# RSL15 register map
Vendor: ONSemiconductor; Series: RSL15 Series; File version: 1.0
CPU: CM33 r0p4, little endian, MPU, FPU, 3 interrupt priority bits
Registers are 32-bit, read-write, reset 0x0 unless marked. A register's access mark holds for its fields unless they carry their own. Offsets are from the block's base; [hi:lo] are bit positions; {n}, {i} and the like mark numbered series.

## RF0 (part 3 of 3) — RF Front-End 2.4 GHz
Base 0x40040800
Same registers: RF1 0x40040A00, RF2 0x40040C00
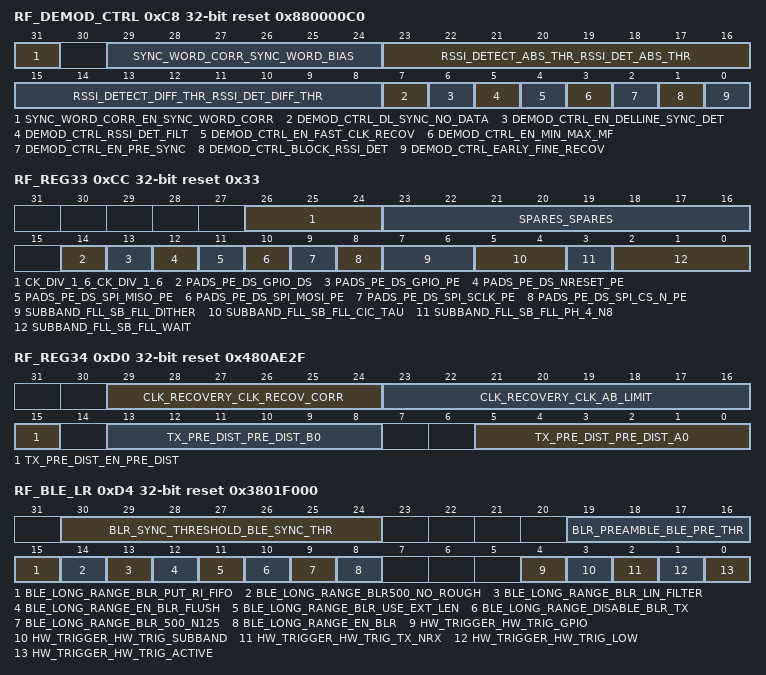
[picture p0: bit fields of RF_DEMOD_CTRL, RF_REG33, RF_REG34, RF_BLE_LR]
0xC8 RF_DEMOD_CTRL reset 0x880000C0 — DEMOD_CTRL
  [31] SYNC_WORD_CORR_EN_SYNC_WORD_CORR — Sync word bias correction with RSSI detection (banked)
    0=SYNC_WORD_CORR_EN_SYNC_WORD_CORR_DISABLE (Disable the sync word bias correction with RSSI detection); 1=SYNC_WORD_CORR_EN_SYNC_WORD_CORR_ENABLE (Enable the sync word bias correction with RSSI detection)
  [29:24] SYNC_WORD_CORR_SYNC_WORD_BIAS — Set the sync word bias (banked)
    8=SYNC_WORD_CORR_SYNC_WORD_BIAS_DEFAULT (Without the phase ADC rescaler, it's 8*mod_idx)
  [23:16] RSSI_DETECT_ABS_THR_RSSI_DET_ABS_THR — Threshold used for absolute RSSI detection
    0=RSSI_DETECT_ABS_THR_RSSI_DET_ABS_THR_DEFAULT
  [15:8] RSSI_DETECT_DIFF_THR_RSSI_DET_DIFF_THR — Threshold used for differential RSSI detection
    0=RSSI_DETECT_DIFF_THR_RSSI_DET_DIFF_THR_DEFAULT
  [7] DEMOD_CTRL_DL_SYNC_NO_DATA — No data going through the demodulator, until the delay line detects the sync word (banked)
    0=DEMOD_CTRL_DL_SYNC_NO_DATA_DISABLE; 1=DEMOD_CTRL_DL_SYNC_NO_DATA_ENABLE
  [6] DEMOD_CTRL_EN_DELLINE_SYNC_DET — Sync word detection in the delay line (banked)
    0=DEMOD_CTRL_EN_DELLINE_SYNC_DET_DISABLE (Disable the sync word detection in the delay line); 1=DEMOD_CTRL_EN_DELLINE_SYNC_DET_ENABLE (Enable the sync word detection in the delay line)
  [5] DEMOD_CTRL_RSSI_DET_FILT — Additional filtering on the RSSI value (banked)
    0=DEMOD_CTRL_RSSI_DET_FILT_DISABLE (Dont' add an additional filtering on the RSSI value); 1=DEMOD_CTRL_RSSI_DET_FILT_ENABLE (Add an additional filtering on the RSSI value)
  [4] DEMOD_CTRL_EN_FAST_CLK_RECOV — Clock recovery during the resto of the preamble (banked)
    0=DEMOD_CTRL_EN_FAST_CLK_RECOV_NOMINAL (Keep nominal clock recovery during the resto of the preamble); 1=DEMOD_CTRL_EN_FAST_CLK_RECOV_SPEED (Speed up the clock recovery during the resto of the preamble)
  [3] DEMOD_CTRL_EN_MIN_MAX_MF — Min max algo after the matched filter (banked)
    0=DEMOD_CTRL_EN_MIN_MAX_MF_DISABLE (Disable the min max algo after the matched filter); 1=DEMOD_CTRL_EN_MIN_MAX_MF_ENABLE (Enable the min max algo after the matched filter)
  [2] DEMOD_CTRL_EN_PRE_SYNC — Sync detection on the non-delayed path (banked)
    0=DEMOD_CTRL_EN_PRE_SYNC_DISABLE (Disable the sync detection on the non-delayed path); 1=DEMOD_CTRL_EN_PRE_SYNC_ENABLE (Enable the sync detection on the non-delayed path)
  [1] DEMOD_CTRL_BLOCK_RSSI_DET — RSSI detection during the slow-down period (banked)
    0=DEMOD_CTRL_BLOCK_RSSI_DET_DISABLE (Keep the rssi detection during the slow-down period); 1=DEMOD_CTRL_BLOCK_RSSI_DET_ENABLE (Block the rssi detection during the slow-down period)
  [0] DEMOD_CTRL_EARLY_FINE_RECOV — Early fine recovery after the packet detection or pre-sync (banked)
    0=DEMOD_CTRL_EARLY_FINE_RECOV_DISABLE (Disable the early fine recovery); 1=DEMOD_CTRL_EARLY_FINE_RECOV_ENABLE (Enable the early fine recovery)
0xCC RF_REG33 reset 0x33 — REG33
  [26:24] CK_DIV_1_6_CK_DIV_1_6 — Clock division factor for ck_div_1_6
    0=CK_DIV_1_6_NO_CLOCK (No clock is generated); {v}=CK_DIV_1_6_PRESCALE_{v} (v=1..7)
  [23:16] SPARES_SPARES — Spare bits
  [14] PADS_PE_DS_GPIO_DS — Increased drive strength of the digital pads
    0=PADS_PE_DS_GPIO_DS_DISABLE (Disable the increased drive strength of the digital pads); 1=PADS_PE_DS_GPIO_DS_ENABLE (Enable the increased drive strength of the digital pads)
  [13] PADS_PE_DS_GPIO_PE — Pull-up of the GPIO pads
    0=PADS_PE_DS_GPIO_PE_DISABLE (Disable the pull-up of the GPIO pads); 1=PADS_PE_DS_GPIO_PE_ENABLE (Enable the pull-up of the GPIO pads)
  [12] PADS_PE_DS_NRESET_PE — Pull-up of the NRESET pads
    0=PADS_PE_DS_NRESET_PE_DISABLE (Disable the pull-up of the NRESET pads); 1=PADS_PE_DS_NRESET_PE_ENABLE (Enable the pull-up of the NRESET pads)
  [11] PADS_PE_DS_SPI_MISO_PE — Pull-up of the SPI MISO pads
    0=PADS_PE_DS_SPI_MISO_PE_DISABLE (Disable the pull-up of the SPI MISO pads); 1=PADS_PE_DS_SPI_MISO_PE_ENABLE (Enable the pull-up of the SPI MISO pads)
  [10] PADS_PE_DS_SPI_MOSI_PE — Pull-up of the SPI MOSI pads
    0=PADS_PE_DS_SPI_MOSI_PE_DISABLE (Disable the pull-up of the SPI MOSI pads); 1=PADS_PE_DS_SPI_MOSI_PE_ENABLE (Enable the pull-up of the SPI MOSI pads)
  [9] PADS_PE_DS_SPI_SCLK_PE — Pull-up of the SPI CLK pads
    0=PADS_PE_DS_SPI_SCLK_PE_DISABLE (Disable the pull-up of the SPI CLK pads); 1=PADS_PE_DS_SPI_SCLK_PE_ENABLE (Enable the pull-up of the SPI CLK pads)
  [8] PADS_PE_DS_SPI_CS_N_PE — Pull-up of the SPI CSN pads
    0=PADS_PE_DS_SPI_CS_N_PE_DISABLE (Disable the pull-up of the SPI CSN pads); 1=PADS_PE_DS_SPI_CS_N_PE_ENABLE (Enable the pull-up of the SPI CSN pads)
  [7:6] SUBBAND_FLL_SB_FLL_DITHER — Select the dithering
    0=SUBBAND_FLL_SB_FLL_DITHER_OFF (No dithering); 1=SUBBAND_FLL_SB_FLL_DITHER_PN9 (PN9 positive); 2=SUBBAND_FLL_SB_FLL_DITHER_PN10 (PN10 negative); 3=SUBBAND_FLL_SB_FLL_DITHER_PN9_PN10 (PN9+PN10)
  [5:4] SUBBAND_FLL_SB_FLL_CIC_TAU — Set the CIC decimator factor
    0=Decimate by 16; 1=Decimate by 32; 2=Decimate by 64; 3=Decimate by 128
  [3] SUBBAND_FLL_SB_FLL_PH_4_N8 — Phases in the frequency detector
    0=Use 8 phases in the frequency detector; 1=Use 4 phases in the frequency detector
  [2:0] SUBBAND_FLL_SB_FLL_WAIT — Set the number of CIC samples before stopping the FLL
    3=SUBBAND_FLL_SB_FLL_WAIT_DEFAULT
0xD0 RF_REG34 reset 0x480AE2F — REG34
  [29:24] CLK_RECOVERY_CLK_RECOV_CORR — Number of samples that covers the clock recovery correlator
    4=CLK_RECOVERY_CLK_RECOV_CORR_DEFAULT
  [23:16] CLK_RECOVERY_CLK_AB_LIMIT — Time constant for switch the clock phase if chosen wrong in clk recovery algorithm
    128=CLK_RECOVERY_CLK_AB_LIMIT_DEFAULT
  [15] TX_PRE_DIST_EN_PRE_DIST — Tx pre-distortion filter (banked)
    0=TX_PRE_DIST_EN_PRE_DIST_DISABLE (Disable the Tx pre-distortion filter); 1=TX_PRE_DIST_EN_PRE_DIST_ENABLE (Enable the Tx pre-distortion filter)
  [13:8] TX_PRE_DIST_PRE_DIST_B0 — Coefficient b0 of the Tx pre-distortion filter (banked)
    46=TX_PRE_DIST_PRE_DIST_B0_DEFAULT (The coefficient value is the (pre_dist_b0+64)/128)
  [5:0] TX_PRE_DIST_PRE_DIST_A0 — Coefficient a0 of the Tx pre-distortion filter (banked)
    47=TX_PRE_DIST_PRE_DIST_A0_DEFAULT (The coefficient value is the (pre_dist_a0+64)/128)
0xD4 RF_BLE_LR reset 0x3801F000 — BLE_LR
  [30:24] BLR_SYNC_THRESHOLD_BLE_SYNC_THR — Threshold for the BLR sync word detector
    56=BLR_SYNC_THRESHOLD_BLE_SYNC_THR_DEFAULT (Unsigned value smaller than 64)
  [19:16] BLR_PREAMBLE_BLE_PRE_THR — Threshold for the BLR preamble detector
    1=BLR_PREAMBLE_BLE_PRE_THR_DEFAULT (Unsigned value)
  [15] BLE_LONG_RANGE_BLR_PUT_RI_FIFO — During the reception the RI (rate indicator) is put into the Rx FIFO (banked)
    0=BLE_LONG_RANGE_BLR_PUT_RI_FIFO_DISABLE (Do not put RI in the RX FIFO); 1=BLE_LONG_RANGE_BLR_PUT_RI_FIFO_ENABLE (Put RI in the RX FIFO)
  [14] BLE_LONG_RANGE_BLR500_NO_ROUGH — Rough recovery is stopped during the 500kbps payloads of BLR packets (banked)
    0=BLE_LONG_RANGE_BLR500_NO_ROUGH_NO_STOP (Rough recovery is not stopped); 1=BLE_LONG_RANGE_BLR500_NO_ROUGH_STOP (Rough recovery is stopped)
  [13] BLE_LONG_RANGE_BLR_LIN_FILTER — Matched filter (banked)
    0=BLE_LONG_RANGE_BLR_LIN_FILTER_DISABLE (The matched filter is not linear in BLR mode); 1=BLE_LONG_RANGE_BLR_LIN_FILTER_ENABLE (The matched filter is linear in BLR mode)
  [12] BLE_LONG_RANGE_EN_BLR_FLUSH — Viterbi path 0 flushing at the end of the packet (banked)
    0=BLE_LONG_RANGE_EN_BLR_FLUSH_DISABLE (The Viterbi path 0 is not flushed at 2Mbps); 1=BLE_LONG_RANGE_EN_BLR_FLUSH_ENABLE (The Viterbi path 0 is flushed at 2Mbps)
  [11] BLE_LONG_RANGE_BLR_USE_EXT_LEN — BLR_PKT_LEN for flushing out the Viterbi (banked)
    0=BLE_LONG_RANGE_BLR_USE_EXT_LEN_NOT_USED (The value in BLR_PKT_LEN will not be used for the flush out of the Viterbi at the end of the packet); 1=BLE_LONG_RANGE_BLR_USE_EXT_LEN_USED (The value in BLR_PKT_LEN will be used for the flush out of the Viterbi at the end of the packet)
  [10] BLE_LONG_RANGE_DISABLE_BLR_TX — Long Range feature in Tx mode (banked)
    0=BLE_LONG_RANGE_DISABLE_BLR_TX_ENABLE (Long Range feature is enabled in Tx mode); 1=BLE_LONG_RANGE_DISABLE_BLR_TX_DISABLE (Long Range feature is disabled in Tx mode)
  [9] BLE_LONG_RANGE_BLR_500_N125 — Data rate selection (banked)
    0=125 kbps mode is used; 1=500 kbps mode is used
  [8] BLE_LONG_RANGE_EN_BLR — BLE long range mode (banked)
    0=BLE_LONG_RANGE_EN_BLR_DISABLE (Disable the BLE long range mode); 1=BLE_LONG_RANGE_EN_BLR_ENABLE (Enable the BLE long range mode)
  [4] HW_TRIGGER_HW_TRIG_GPIO — HW trigger is mapped on the GPIO instead of the Tx_on signal 0x0
    0=HW_TRIGGER_HW_TRIG_GPIO_TX_ON (HW trigger mapped on TX_ON); 1=HW_TRIGGER_HW_TRIG_GPIO (HW trigger mapped on GPIO)
  [3] HW_TRIGGER_HW_TRIG_SUBBAND — Activate the sub-band selection during the Tx activation
    0=HW_TRIGGER_HW_TRIG_SUBBAND_NOT_ACTIVE (HW trigger does not active sub-band selection); 1=HW_TRIGGER_HW_TRIG_SUBBAND_ACTIVE (HW trigger actives sub-band selection)
  [2] HW_TRIGGER_HW_TRIG_TX_NRX — Activate the Tx mode
    0=HW_TRIGGER_HW_TRIG_TX_NRX_RX (HW trigger actives RX mode); 1=HW_TRIGGER_HW_TRIG_TX_NRX_TX (HW trigger actives TX mode)
  [1] HW_TRIGGER_HW_TRIG_LOW — Set the trigger polarity
    0=HW_TRIGGER_HW_TRIG_LOW_LOW (HW trigger active low); 1=HW_TRIGGER_HW_TRIG_LOW_HIGH (HW trigger active high)
  [0] HW_TRIGGER_HW_TRIG_ACTIVE — Enable HW trigger
    0=HW_TRIGGER_HW_TRIG_ACTIVE_DISABLE (Disable HW trigger); 1=HW_TRIGGER_HW_TRIG_ACTIVE_ENABLE (Enable HW trigger)
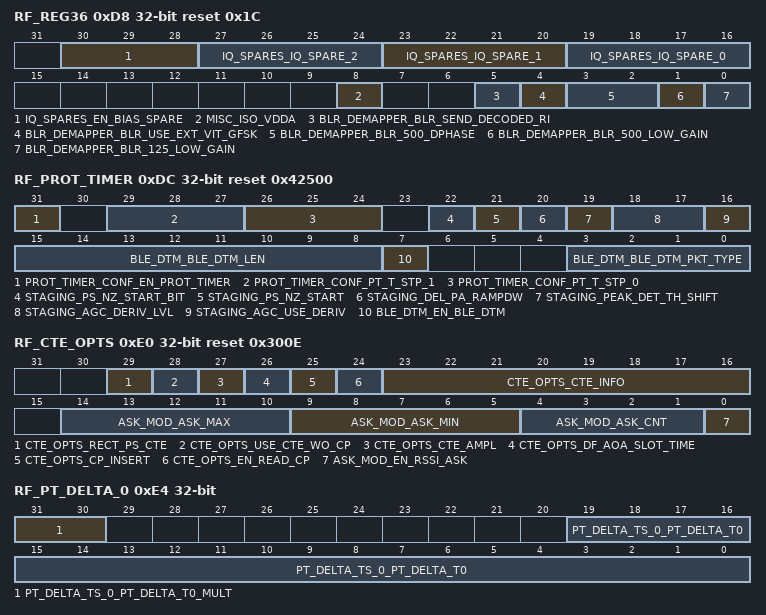
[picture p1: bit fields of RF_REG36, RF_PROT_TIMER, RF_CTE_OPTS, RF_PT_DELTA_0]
0xD8 RF_REG36 reset 0x1C — REG36
  [30:28] IQ_SPARES_EN_BIAS_SPARE — Enable for IQ spares
    0=IQ_SPARES_EN_BIAS_SPARE_DEFAULT
  [27:24] IQ_SPARES_IQ_SPARE_2 — Spare bias 2
    0=IQ_SPARES_IQ_SPARE_2_DEFAULT
  [23:20] IQ_SPARES_IQ_SPARE_1 — Spare bias 1
    0=IQ_SPARES_IQ_SPARE_1_DEFAULT
  [19:16] IQ_SPARES_IQ_SPARE_0 — Spare bias 0
    0=IQ_SPARES_IQ_SPARE_0_DEFAULT
  [8] MISC_ISO_VDDA — Isolate VDDA signals
    0=MISC_ISO_VDDA_NOT_ISOLATE (Do not isolate VDDA signals); 1=MISC_ISO_VDDA_ISOLATE (Isolate VDDA signals)
  [5] BLR_DEMAPPER_BLR_SEND_DECODED_RI — Fully decode the rate indicator
    0=BLR_DEMAPPER_BLR_SEND_DECODED_RI_DISABLE (Rate indicator is not fully decoded and decision made is sent instead); 1=BLR_DEMAPPER_BLR_SEND_DECODED_RI_ENABLE (Rate indicator is fully decoded)
  [4] BLR_DEMAPPER_BLR_USE_EXT_VIT_GFSK — 500kbps BLR uses the Viterbi GFSK decision
    0=BLR_DEMAPPER_BLR_USE_EXT_VIT_GFSK_DISABLE (Do not use the Viterbi GFSK decision); 1=BLR_DEMAPPER_BLR_USE_EXT_VIT_GFSK_ENABLE (Use the Viterbi GFSK decision)
  [3:2] BLR_DEMAPPER_BLR_500_DPHASE — Set the distance between samples for the phase to frequency conversion in S2 mode
    0=2 samples; 1=4 samples; 2=6 samples; 3=8 samples
  [1] BLR_DEMAPPER_BLR_500_LOW_GAIN — Set the low gain in S2 mode
    0=BLR_DEMAPPER_BLR_500_LOW_GAIN_DISABLE (Do not set low gain in S2 mode); 1=BLR_DEMAPPER_BLR_500_LOW_GAIN_ENABLE (Set low gain in S2 mode)
  [0] BLR_DEMAPPER_BLR_125_LOW_GAIN — Set the low gain in S8 mode
    0=BLR_DEMAPPER_BLR_125_LOW_GAIN_DISABLE (Do not set low gain in S8 mode); 1=BLR_DEMAPPER_BLR_125_LOW_GAIN_ENABLE (Set low gain in S8 mode)
0xDC RF_PROT_TIMER reset 0x42500 — PROT_TIMER
  [31] PROT_TIMER_CONF_EN_PROT_TIMER — Enable the protocol timer
    0=PROT_TIMER_CONF_EN_PROT_TIMER_DISABLE (Disable protocol timer); 1=PROT_TIMER_CONF_EN_PROT_TIMER_ENABLE (Enable protocol timer)
  [29:27] PROT_TIMER_CONF_PT_T_STP_1 — Configure the time stamp 1
    0=PROT_TIMER_CONF_PT_T_STP_1_DEFAULT
  [26:24] PROT_TIMER_CONF_PT_T_STP_0 — Configure the time stamp 0
    0=PROT_TIMER_CONF_PT_T_STP_0_NO_STAMP (No time stamp); 1=PROT_TIMER_CONF_PT_T_STP_0_TIMER_TRIGGER (Protocol timer trigger); 4=PROT_TIMER_CONF_PT_T_STP_0_TRIGGER_TX_STOP (TX stop trigger); 5=PROT_TIMER_CONF_PT_T_STP_0_TRIGGER_RX_SYNC (RX sync trigger); 6=PROT_TIMER_CONF_PT_T_STP_0_TRIGGER_RX_STOP (RX stop trigger); 7=PROT_TIMER_CONF_PT_T_STP_0_TRIGGER_RX_RECEIVED (RX received trigger)
  [22] STAGING_PS_NZ_START_BIT — Select the frequency offset
    0=Select bit 0 (-250 kHz offset); 1=Select bit 1 (+250 kHz offset)
  [21] STAGING_PS_NZ_START — Start the pulse shaper with a +/- 250 kHz frequency offset
    0=STAGING_PS_NZ_START_NO_OFFSET (Do not start the pulse shaper with a frequency offset); 1=STAGING_PS_NZ_START_OFFSET (Start the pulse shaper with a frequency offset)
  [20] STAGING_DEL_PA_RAMPDW — Delay the PA ramp-down by 4.5 us
    0=STAGING_DEL_PA_RAMPDW_NO_DELAY (Do not delay PA ramp down); 1=STAGING_DEL_PA_RAMPDW_DELAY (Delay PA ramp down)
  [19] STAGING_PEAK_DET_TH_SHIFT — Peak detector threshold shift
    0=STAGING_PEAK_DET_TH_SHIFT_NO_SHIFT (Do not shift peak detector); 1=STAGING_PEAK_DET_TH_SHIFT_SHIFT (Shift peak detector)
  [18:17] STAGING_AGC_DERIV_LVL — Select the AGC derivative level
    0=Level 16; 1=Level 24; 2=Level 32; 3=Level 48
  [16] STAGING_AGC_USE_DERIV — AGC algorithm uses the derivative information to accelerate the AGC settling
    0=STAGING_AGC_USE_DERIV_NOT_USED (Do not use derivative information); 1=STAGING_AGC_USE_DERIV_USED (Use derivative information)
  [15:8] BLE_DTM_BLE_DTM_LEN — Set the BLE DTM packet length
    37=BLE_DTM_BLE_DTM_LEN_DEFAULT
  [7] BLE_DTM_EN_BLE_DTM — Enable the BLE DTM automatic packets
    0=BLE_DTM_EN_BLE_DTM_DISABLE (Disable BLE DTM automatic packets); 1=BLE_DTM_EN_BLE_DTM_ENABLE (Enable BLE DTM automatic packets)
  [3:0] BLE_DTM_BLE_DTM_PKT_TYPE — Set the BLE DTM packet type (see Bluetooth specification)
    0=BLE_DTM_BLE_DTM_PKT_TYPE_DEFAULT
0xE0 RF_CTE_OPTS reset 0x300E — CTE_OPTS
  [29] CTE_OPTS_RECT_PS_CTE — Use rectangular pulse shape during the CTE
    0=CTE_OPTS_RECT_PS_CTE_DISABLE (Disable CTE with rectangular pulse shaping); 1=CTE_OPTS_RECT_PS_CTE_ENABLE (Enable CTE with rectangular pulse shaping)
  [28] CTE_OPTS_USE_CTE_WO_CP — Enable the CTE without reading or inserting the CP
    0=CTE_OPTS_USE_CTE_WO_CP_DISABLE (Disable CTE without reading CP); 1=CTE_OPTS_USE_CTE_WO_CP_ENABLE (Enable CTE without reading CP)
  [27] CTE_OPTS_CTE_AMPL — Enable the usage of the RSSI values to adapt the amplitude of the IQ signal based to the RSSI value
    0=CTE_OPTS_CTE_AMPL_DISABLE (Disable RSSI for IQ signal validation); 1=CTE_OPTS_CTE_AMPL_ENABLE (Enable RSSI for IQ signal validation)
  [26] CTE_OPTS_DF_AOA_SLOT_TIME — Indicate the switching/sampling slot period for AoA
    0=1us switching period; 1=2us switching period
  [25] CTE_OPTS_CP_INSERT — Force the CP bit in the packet header to 1
    0=CTE_OPTS_CP_INSERT_DISABLE (Disable forcing CP bit to 1); 1=CTE_OPTS_CP_INSERT_ENABLE (Enable forcing CP bit to 1)
  [24] CTE_OPTS_EN_READ_CP — CP bit is read in the packet header (BLE standard)
    0=CTE_OPTS_EN_READ_CP_DISABLE (Disable reading CP bit); 1=CTE_OPTS_EN_READ_CP_ENABLE (Enable reading CP bit)
  [23:16] CTE_OPTS_CTE_INFO — Set the CTEInfo field in the packet header while cp_insert is set to 1
    0=CTE_OPTS_CTE_INFO_DEFAULT
  [14:10] ASK_MOD_ASK_MAX — Set the maximum value for the ASK modulation
    12=ASK_MOD_ASK_MAX_DEFAULT
  [9:5] ASK_MOD_ASK_MIN — Set the minimum value for the ASK modulation
    0=ASK_MOD_ASK_MIN_DEFAULT
  [4:1] ASK_MOD_ASK_CNT — Set the how long to count for the ASK modulation
    7=ASK_MOD_ASK_CNT_DEFAULT
  [0] ASK_MOD_EN_RSSI_ASK — PA will perform an ASK modulation
    0=ASK_MOD_EN_RSSI_ASK_DISABLE (Disable PA ASK modulation); 1=ASK_MOD_EN_RSSI_ASK_ENABLE (Enable PA ASK modulation)
0xE4 RF_PT_DELTA_0 — PT_DELTA_0
  [31:30] PT_DELTA_TS_0_PT_DELTA_T0_MULT — Multiplier for the delta t0
    0=PT_DELTA_TS_0_PT_DELTA_T0_MULT_DEFAULT
  [19:0] PT_DELTA_TS_0_PT_DELTA_T0 — Delta t0 for the protocol timer
    0=PT_DELTA_TS_0_PT_DELTA_T0_DEFAULT
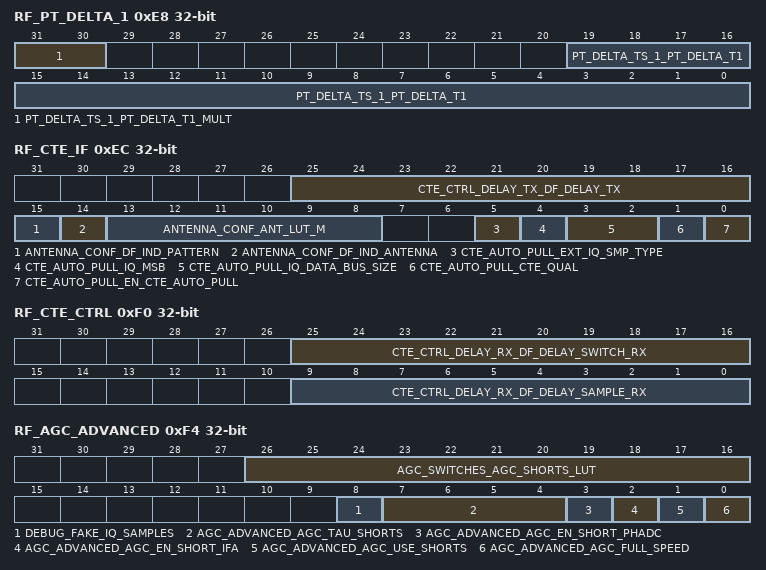
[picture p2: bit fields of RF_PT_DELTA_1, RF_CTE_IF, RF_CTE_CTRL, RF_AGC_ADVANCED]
0xE8 RF_PT_DELTA_1 — PT_DELTA_1
  [31:30] PT_DELTA_TS_1_PT_DELTA_T1_MULT — Multiplier for the delta t1
    0=PT_DELTA_TS_1_PT_DELTA_T1_MULT_DEFAULT
  [19:0] PT_DELTA_TS_1_PT_DELTA_T1 — Delta t1 for the protocol timer
    0=PT_DELTA_TS_1_PT_DELTA_T1_DEFAULT
0xEC RF_CTE_IF — CTE_IF
  [25:16] CTE_CTRL_DELAY_TX_DF_DELAY_TX — Delay (in 62.5ns) form the serializer up to the antenna in direction finding (banked)
    0=CTE_CTRL_DELAY_TX_DF_DELAY_TX_DEFAULT
  [15] ANTENNA_CONF_DF_IND_PATTERN — Separate the antenna switching pattern from the reference one
    0=ANTENNA_CONF_DF_IND_PATTERN_DISABLE (Disable the seperation of the antenna switching pattern); 1=ANTENNA_CONF_DF_IND_PATTERN_ENABLE (Enable the seperation of the antenna switching pattern)
  [14] ANTENNA_CONF_DF_IND_ANTENNA — Make the antenna for DF independent from the rest of the packet
    0=ANTENNA_CONF_DF_IND_ANTENNA_DISABLE (Disable the independancy of the antenna); 1=ANTENNA_CONF_DF_IND_ANTENNA_ENABLE (Enable the independancy of the antenna)
  [13:8] ANTENNA_CONF_ANT_LUT_M — Number of states used (-1) in the antenna LUT
    0=ANTENNA_CONF_ANT_LUT_M_DEFAULT
  [5] CTE_AUTO_PULL_EXT_IQ_SMP_TYPE — Select the external IQ sample signal qualifier type
    0=CTE_AUTO_PULL_EXT_IQ_SMP_TYPE_PULSE (Pulse); 1=CTE_AUTO_PULL_EXT_IQ_SMP_TYPE_TOGGLE (Toggle)
  [4] CTE_AUTO_PULL_IQ_MSB — Select which signal is sent over the MSB in case of a 16bits buffers
    0=CTE_AUTO_PULL_IQ_MSB_Q (I LSB, Q MSB); 1=CTE_AUTO_PULL_IQ_MSB_I (Q LSB, I MSB)
  [3:2] CTE_AUTO_PULL_IQ_DATA_BUS_SIZE — Select the bus data size of IQ signals
    0=4 bits; 1=8 bits; 2=16 bits
  [1] CTE_AUTO_PULL_CTE_QUAL — Select the CTE data qualifier
    0=CTE_AUTO_PULL_CTE_QUAL_TOGGLE (Toggling signal); 1=CTE_AUTO_PULL_CTE_QUAL_CLOCK (Clock signal)
  [0] CTE_AUTO_PULL_EN_CTE_AUTO_PULL — Enable the automatic push of CTE data to an external IP
    0=CTE_AUTO_PULL_EN_CTE_AUTO_PULL_DISABLE (Disable automatic push of CTE data); 1=CTE_AUTO_PULL_EN_CTE_AUTO_PULL_ENABLE (Enable automatic push of CTE data)
0xF0 RF_CTE_CTRL — CTE_CTRL
  [25:16] CTE_CTRL_DELAY_RX_DF_DELAY_SWITCH_RX — Delay (in 62.5ns) from the antenna up to the deserializer in direction finding (banked)
    0=CTE_CTRL_DELAY_RX_DF_DELAY_SWITCH_RX_DEFAULT
  [9:0] CTE_CTRL_DELAY_RX_DF_DELAY_SAMPLE_RX — Delay (in 62.5ns) from the matched filter up to the deserializer in direction finding (banked)
    0=CTE_CTRL_DELAY_RX_DF_DELAY_SAMPLE_RX_DEFAULT
0xF4 RF_AGC_ADVANCED — AGC_ADVANCED
  [26:16] AGC_SWITCHES_AGC_SHORTS_LUT — Array of values that indicates if the highpass shorts must be set for the AGC state passage from n -> n+1
    0=AGC_SWITCHES_AGC_SHORTS_LUT_DEFAULT
  [8] DEBUG_FAKE_IQ_SAMPLES — Generate fake IQ samples
    0=DEBUG_FAKE_IQ_SAMPLES_DISABLE (Disable fake IQ samples); 1=DEBUG_FAKE_IQ_SAMPLES_ENABLE (Enable fake IQ samples)
  [7:4] AGC_ADVANCED_AGC_TAU_SHORTS — Time constant that indicates the time that shorts must be on
    0=AGC_ADVANCED_AGC_TAU_SHORTS_DEFAULT
  [3] AGC_ADVANCED_AGC_EN_SHORT_PHADC — Enable the short on the phase ADC highpass filter
    0=AGC_ADVANCED_AGC_EN_SHORT_PHADC_DISABLE (Disable the short on the phase ADC highpass filter); 1=AGC_ADVANCED_AGC_EN_SHORT_PHADC_ENABLE (Enable the short on the phase ADC highpass filter)
  [2] AGC_ADVANCED_AGC_EN_SHORT_IFA — Enable the short on the IFA highpass filter
    0=AGC_ADVANCED_AGC_EN_SHORT_IFA_DISABLE (Disable the short on the IFA highpass filter); 1=AGC_ADVANCED_AGC_EN_SHORT_IFA_ENABLE (Enable the short on the IFA highpass filter)
  [1] AGC_ADVANCED_AGC_USE_SHORTS — Enable the usage of the shorts located in the BB path
    0=AGC_ADVANCED_AGC_USE_SHORTS_DISABLE (Disable using shorts located in BB path); 1=AGC_ADVANCED_AGC_USE_SHORTS_ENABLE (Enable using shorts located in BB path)
  [0] AGC_ADVANCED_AGC_FULL_SPEED — Enable the maximum speed in AGC
    0=AGC_ADVANCED_AGC_FULL_SPEED_DISABLE (Disable maximum AGC speed); 1=AGC_ADVANCED_AGC_FULL_SPEED_ENABLE (Enable maximum speed AGC)
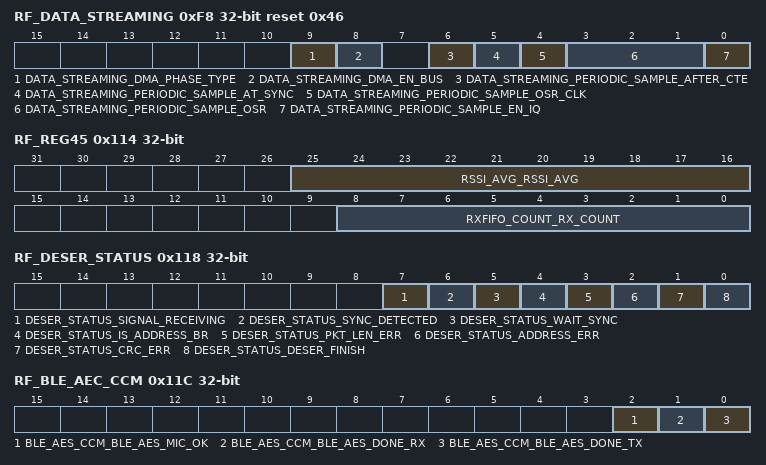
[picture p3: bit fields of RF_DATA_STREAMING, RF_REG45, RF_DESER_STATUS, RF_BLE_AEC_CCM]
0xF8 RF_DATA_STREAMING reset 0x46 — DATA_STREAMING
  [9] DATA_STREAMING_DMA_PHASE_TYPE — Use the phase after the rescaler instead of the raw phase from phase ADC (banked)
    0=DATA_STREAMING_DMA_PHASE_TYPE_PHADC (Use the raw phase from the phase ADC); 1=DATA_STREAMING_DMA_PHASE_TYPE_RESCALER (Use the phase after the rescaler)
  [8] DATA_STREAMING_DMA_EN_BUS — Enable the DMA bus on the IP interface (banked)
    0=DATA_STREAMING_DMA_BUS_DISABLE (Enable the DMA bus on the IP interface); 1=DATA_STREAMING_DMA_BUS_ENABLE (Disable the DMA bus on the IP interface)
  [6] DATA_STREAMING_PERIODIC_SAMPLE_AFTER_CTE — Restart sampling after the CTE period (banked)
    0=DATA_STREAMING_PERIODIC_SAMPLE_AFTER_CTE_DISABLE (Stop sampling after the CTE event); 1=DATA_STREAMING_PERIODIC_SAMPLE_AFTER_CTE_ENABLE (Restart sampling after the CTE event)
  [5] DATA_STREAMING_PERIODIC_SAMPLE_AT_SYNC — Start sampling at the sync detection signal from the delay line (banked)
    0=DATA_STREAMING_PERIODIC_SAMPLE_AT_SYNC_DISABLE (Sample at the Rx activation); 1=DATA_STREAMING_PERIODIC_SAMPLE_AT_SYNC_ENABLE (Sample at the sync detection signal from the delay line)
  [4] DATA_STREAMING_PERIODIC_SAMPLE_OSR_CLK — Oversample (8x) the reference clock of the periodic sample (banked)
    0=DATA_STREAMING_PERIODIC_SAMPLE_OSR_CLK_DISABLE (Use the system clock); 1=DATA_STREAMING_PERIODIC_SAMPLE_OSR_CLK_ENABLE (Oversample the reference clock of the periodic sample)
  [3:1] DATA_STREAMING_PERIODIC_SAMPLE_OSR — Division factor (-1) of for the sampling period of the periodic IQ sampling (banked)
    3=DATA_STREAMING_PERIODIC_SAMPLE_OSR_DEFAULT
  [0] DATA_STREAMING_PERIODIC_SAMPLE_EN_IQ — Sample periodically I and Q channels after the matched filter and put into the IQ FIFO (banked)
    0=DATA_STREAMING_PERIODIC_SAMPLE_IQ_DISABLE (Disable periodical sampling); 1=DATA_STREAMING_PERIODIC_SAMPLE_IQ_ENABLE (Enable periodical sampling)
0xFC RF_REVISION ro reset 0x30000000 — REVISION
  [31:24] CHIP_ID — Remapped register of CHIP_ID
    48=CHIP_ID_DEFAULT (The remapped registers are accessible over SPI only)
0x100 RF_FSM_CTRL (reset mask 0xFFFF0707) — FSM_CTRL
  [31:30] RXFIFO_STATUS_RX_BIST_ERRORS ro — Rx FIFO BIST result
    0=RXFIFO_STATUS_RX_BIST_NO_ERROR (No error); 1=RXFIFO_STATUS_RX_BIST_CKBD (Error in checkboard test); 2=RXFIFO_STATUS_RX_BIST_ICKBD (Error in inversed checkboard test); 3=RXFIFO_STATUS_RX_BIST_DECODER (Error in decoder test)
  [29] RXFIFO_STATUS_RX_NEAR_UNDERFLOW ro — Rx FIFO near underflow
    0=RXFIFO_STATUS_RX_NO_NEAR_UNDERFLOW (No Rx FIFO near underflow occurred); 1=RXFIFO_STATUS_RX_NEAR_UNDERFLOW (Rx FIFO near underflow occurred)
  [28] RXFIFO_STATUS_RX_NEAR_OVERFLOW ro — Rx FIFO near overflow
    0=RXFIFO_STATUS_RX_NO_NEAR_OVERFLOW (No Rx FIFO near overflow occurred); 1=RXFIFO_STATUS_RX_NEAR_OVERFLOW (Rx FIFO near verflow occurred)
  [27] RXFIFO_STATUS_RX_UNDERFLOW ro — Rx FIFO underflow
    0=RXFIFO_STATUS_RX_NO_UNDERFLOW (No Rx FIFO underflow occurred); 1=RXFIFO_STATUS_RX_UNDERFLOW (Rx FIFO underflow occurred)
  [26] RXFIFO_STATUS_RX_OVERFLOW ro — Rx FIFO overflow
    0=RXFIFO_STATUS_RX_NO_OVERFLOW (No Rx FIFO overflow occurred); 1=RXFIFO_STATUS_RX_OVERFLOW (Rx FIFO overflow occurred)
  [25] RXFIFO_STATUS_RX_FULL ro — Rx FIFO full
    0=RXFIFO_STATUS_RX_NOT_FULL (Rx FIFO is not full); 1=RXFIFO_STATUS_RX_FULL (Rx FIFO is full)
  [31:25] RXFIFO_STATUS_RX_BIST wo — Start the bist test on the Rx FIFO (code 0x5d)
    0=RXFIFO_STATUS_RX_BIST_DEFAULT
  [24] RXFIFO_STATUS_RX_EMPTY ro — Rx FIFO empty
    0=RXFIFO_STATUS_RX_NOT_EMPTY (Rx FIFO is not empty); 1=RXFIFO_STATUS_RX_EMPTY (Rx FIFO is empty)
  [24] RXFIFO_STATUS_RX_FLUSH wo — Rx FIFO flush
    0=RXFIFO_STATUS_NO_FLUSH (Don't flush Rx FIFO); 1=RXFIFO_STATUS_FLUSH (Flush Rx FIFO)
  [23:22] TXFIFO_STATUS_TX_BIST_ERRORS ro — Tx FIFO BIST result
    0=TXFIFO_STATUS_TX_BIST_NO_ERROR (No error); 1=TXFIFO_STATUS_TX_BIST_CKBD (Error in checkboard test); 2=TXFIFO_STATUS_TX_BIST_ICKBD (Error in inversed checkboard test); 3=TXFIFO_STATUS_TX_BIST_DECODER (Error in decoder test)
  [21] TXFIFO_STATUS_TX_NEAR_UNDERFLOW ro — Tx FIFO near underflow
    0=TXFIFO_STATUS_TX_NO_NEAR_UNDERFLOW (No Tx FIFO near underflow occurred); 1=TXFIFO_STATUS_TX_NEAR_UNDERFLOW (Tx FIFO near underflow occurred)
  [20] TXFIFO_STATUS_TX_NEAR_OVERFLOW ro — Tx FIFO near overflow
    0=TXFIFO_STATUS_TX_NO_NEAR_OVERFLOW (No Tx FIFO near overflow occurred); 1=TXFIFO_STATUS_TX_NEAR_OVERFLOW (Tx FIFO near verflow occurred)
  [19] TXFIFO_STATUS_TX_UNDERFLOW ro — Tx FIFO underflow
    0=TXFIFO_STATUS_TX_NO_UNDERFLOW (No Tx FIFO underflow occurred); 1=TXFIFO_STATUS_TX_UNDERFLOW (Tx FIFO underflow occurred)
  [18] TXFIFO_STATUS_TX_OVERFLOW ro — Tx FIFO overflow
    0=TXFIFO_STATUS_TX_NO_OVERFLOW (No Tx FIFO overflow occurred); 1=TXFIFO_STATUS_TX_OVERFLOW (Tx FIFO overflow occurred)
  [17] TXFIFO_STATUS_TX_FULL ro — Tx FIFO full
    0=TXFIFO_STATUS_TX_NOT_FULL (Tx FIFO is not full); 1=TXFIFO_STATUS_TX_FULL (Tx FIFO is full)
  [23:17] TXFIFO_STATUS_TX_BIST wo — Start the bist test on the Tx FIFO (code 0x5d)
    0=TXFIFO_STATUS_TX_BIST_DEFAULT
  [16] TXFIFO_STATUS_TX_EMPTY ro — Tx FIFO empty
    0=TXFIFO_STATUS_TX_NOT_EMPTY (Tx FIFO is not empty); 1=TXFIFO_STATUS_TX_EMPTY (Tx FIFO is empty)
  [16] TXFIFO_STATUS_TX_FLUSH wo — Tx FIFO flush
    0=TXFIFO_STATUS_NO_FLUSH (Don't flush Tx FIFO); 1=TXFIFO_STATUS_FLUSH (Flush Tx FIFO)
  [10] FSM_STATUS_TX_NRX ro — Select Rx or Tx mode
    0=FSM_STATUS_RX_NTX (Radio is in Rx mode); 1=FSM_STATUS_TX_NRX (Radio is in Tx mode)
  [9:8] FSM_STATUS_STATUS ro — Status of the FSM
    0=FSM_STATUS_IDLE (Nothing is done); 1=FSM_STATUS_TX (Tx mode); 2=FSM_STATUS_RX (Rx mode); 3=FSM_STATUS_SUSPEND (Suspend)
  [3] FSM_MODE_RESET wo — FSM reset
    0=FSM_MODE_NOT_RESET (Not reset FSM); 1=FSM_MODE_RESET (Reset FSM)
  [2] FSM_MODE_RX_MODE ro — Rx status
    0=FSM_MODE_RX_MODE_OFF (No ongoing Rx); 1=FSM_MODE_RX_MODE_ON (Rx is ongoing)
  [2] FSM_MODE_TX_NRX wo — Set the radio in Tx or Rx mode
    0=FSM_MODE_RX_NTX (Set the radio in Rx); 1=FSM_MODE_TX_NRX (Set the radio in Tx)
  [1] FSM_MODE_TX_MODE ro — Tx status
    0=FSM_MODE_TX_MODE_OFF (No ongoing Tx); 1=FSM_MODE_TX_MODE_ON (Tx is ongoing)
  [0] FSM_MODE_N_IDLE ro — FSM status
    0=FSM_MODE_IDLE (FSM is in the Idle mode); 1=FSM_MODE_N_IDLE (FSM is not in the Idle mode)
  [1:0] FSM_MODE_MODE wo — Set the FSM mode
    0=FSM_MODE_MODE_IDLE (Nothing is done); 1=FSM_MODE_MODE_ACTIVATE (Activate); 2=FSM_MODE_MODE_CAL_PLL (Calibrate the PLL); 3=FSM_MODE_MODE_CAL_PLL_TXRX (Calibrate the PLL then Tx/Rx)
0x104 RF_IQFIFO_STATUS — IQFIFO_STATUS
  [24:16] TXFIFO_COUNT_TX_COUNT ro — Number of bytes in the Tx FIFO
    0=TXFIFO_COUNT_TX_COUNT_DEFAULT
  [15:8] IQFIFO_COUNT_IQ_COUNT ro — Number of bytes in the IQ FIFO
    0=IQFIFO_COUNT_IQ_COUNT_DEFAULT
  [7:6] IQFIFO_STATUS_IQ_BIST_ERRORS ro — IQ FIFO BIST result
    0=IQFIFO_STATUS_IQ_BIST_NO_ERROR (No error); 1=IQFIFO_STATUS_IQ_BIST_CKBD (Error in checkboard test); 2=IQFIFO_STATUS_IQ_BIST_ICKBD (Error in inversed checkboard test); 3=IQFIFO_STATUS_IQ_BIST_DECODER (Error in decoder test)
  [5] IQFIFO_STATUS_IQ_NEAR_UNDERFLOW ro — IQ FIFO near underflow
    0=IQFIFO_STATUS_IQ_NO_NEAR_UNDERFLOW (No Tx FIFO near underflow occurred); 1=IQFIFO_STATUS_IQ_NEAR_UNDERFLOW (Tx FIFO near underflow occurred)
  [4] IQFIFO_STATUS_IQ_NEAR_OVERFLOW ro — IQ FIFO near overflow
    0=IQFIFO_STATUS_IQ_NO_NEAR_OVERFLOW (No Tx FIFO near overflow occurred); 1=IQFIFO_STATUS_IQ_NEAR_OVERFLOW (Tx FIFO near overflow occurred)
  [3] IQFIFO_STATUS_IQ_UNDERFLOW ro — IQ FIFO underflow
    0=IQFIFO_STATUS_IQ_NO_UNDERFLOW (No Tx FIFO underflow occurred); 1=IQFIFO_STATUS_IQ_UNDERFLOW (Tx FIFO underflow occurred)
  [2] IQFIFO_STATUS_IQ_OVERFLOW ro — IQ FIFO overflow
    0=IQFIFO_STATUS_IQ_NO_OVERFLOW (No Tx FIFO overflow occurred); 1=IQFIFO_STATUS_IQ_OVERFLOW (Tx FIFO overflow occurred)
  [1] IQFIFO_STATUS_IQ_FULL ro — IQ FIFO full
    0=IQFIFO_STATUS_IQ_NOT_FULL (Tx FIFO is not full); 1=IQFIFO_STATUS_IQ_FULL (Tx FIFO is full)
  [7:1] IQFIFO_STATUS_IQ_BIST wo — Start the BIST test on the IQ FIFO (code 0x5d)
    0=IQFIFO_STATUS_IQ_BIST_DEFAULT
  [0] IQFIFO_STATUS_IQ_EMPTY ro — IQ FIFO empty
    0=IQFIFO_STATUS_IQ_NOT_EMPTY (Tx FIFO is not empty); 1=IQFIFO_STATUS_IQ_EMPTY (Tx FIFO is empty)
  [0] IQFIFO_STATUS_FLUSH wo — IQ FIFO flush
    0=IQFIFO_STATUS_NO_FLUSH (Don't flush Tx FIFO); 1=IQFIFO_STATUS_FLUSH (Flush Tx FIFO)
0x108 RF_TXFIFO reset not defined — TXFIFO
  [7:0] TXFIFO_TX_DATA wo — Data to be sent
    0=TXFIFO_TX_DATA_DEFAULT
0x10C RF_RXFIFO ro — RXFIFO
  [7:0] RXFIFO_RX_DATA — Received data
    0=RXFIFO_RX_DATA_DEFAULT
0x110 RF_IQFIFO ro — IQFIFO
  [7:0] IQFIFO_IQ_DATA — IQ data for AoA or AoD
    0=IQFIFO_IQ_DATA_DEFAULT
0x114 RF_REG45 ro — REG45
  [25:16] RSSI_AVG_RSSI_AVG — Filtered RSSI value
    0=RSSI_AVG_RSSI_AVG_DEFAULT
  [8:0] RXFIFO_COUNT_RX_COUNT — Number of bytes in the Rx FIFO
    0=RXFIFO_COUNT_RX_COUNT_DEFAULT
0x118 RF_DESER_STATUS ro — DESER_STATUS
  [7] DESER_STATUS_SIGNAL_RECEIVING — Deserializer enabling
    0=DESER_STATUS_SIGNAL_RECEIVING_DISABLE (Deserializer is disabled); 1=DESER_STATUS_SIGNAL_RECEIVING_ENABLE (Deserializer is enabled)
  [6] DESER_STATUS_SYNC_DETECTED — Sync word detection
    0=DESER_STATUS_SYNC_NOT_DETECTED (Sync word (pattern) not detected); 1=DESER_STATUS_SYNC_DETECTED (Sync word (pattern) detected)
  [5] DESER_STATUS_WAIT_SYNC — Deserializer waiting for the sync word
    0=DESER_STATUS_WAIT_SYNC_NOT_WAITING (Deserializer is not waiting the sync word); 1=DESER_STATUS_WAIT_SYNC_WAITING (Deserializer is waiting the sync word)
  [4] DESER_STATUS_IS_ADDRESS_BR — Received address
    0=DESER_STATUS_IS_ADDRESS_BR_DISABLE (The received address is not the broadcast address); 1=DESER_STATUS_IS_ADDRESS_BR_ENABLE (The received address is the broadcast address)
  [3] DESER_STATUS_PKT_LEN_ERR — Packet length
    0=DESER_STATUS_PKT_LEN_ERR_NO_ERROR (The packet length is shorter than the maximum acceptable packet length); 1=DESER_STATUS_PKT_LEN_ERR_ERROR (The packet length is longer than the maximum acceptable packet length)
  [2] DESER_STATUS_ADDRESS_ERR — Address error
    0=DESER_STATUS_ADDRESS_ERR_NO_ERROR (No address error detected); 1=DESER_STATUS_ADDRESS_ERR_ERROR (Address error detected)
  [1] DESER_STATUS_CRC_ERR — CRC error
    0=DESER_STATUS_CRC_ERR_NO_ERROR (No CRC error detected); 1=DESER_STATUS_CRC_ERR_ERROR (CRC error detected)
  [0] DESER_STATUS_DESER_FINISH — Deserializer status
    0=DESER_STATUS_DESER_FINISH_BUSY (Deserializer has not yet finished); 1=DESER_STATUS_DESER_FINISH_IDLE (Deserializer has finished)
0x11C RF_BLE_AEC_CCM ro — BLE_AEC_CCM
  [2] BLE_AES_CCM_BLE_AES_MIC_OK — AES CCM MIC error
    0=BLE_AES_CCM_BLE_AES_MIC_OK_ERROR (MIC has been received with errors); 1=BLE_AES_CCM_BLE_AES_MIC_OK_NO_ERROR (MIC has been received without errors)
  [1] BLE_AES_CCM_BLE_AES_DONE_RX — AES CCM packet decoding
    0=BLE_AES_CCM_BLE_AES_DONE_RX_BUSY (BLE AES CCM algorithm has not yet finished the packet decoding); 1=BLE_AES_CCM_BLE_AES_DONE_RX_IDLE (BLE AES CCM algorithm has finished the packet decoding)
  [0] BLE_AES_CCM_BLE_AES_DONE_TX — AES CCM packet encoding
    0=BLE_AES_CCM_BLE_AES_DONE_TX_BUSY (BLE AES CCM algorithm has not yet finished the packet encoding); 1=BLE_AES_CCM_BLE_AES_DONE_TX_IDLE (BLE AES CCM algorithm has finished the packet encoding)
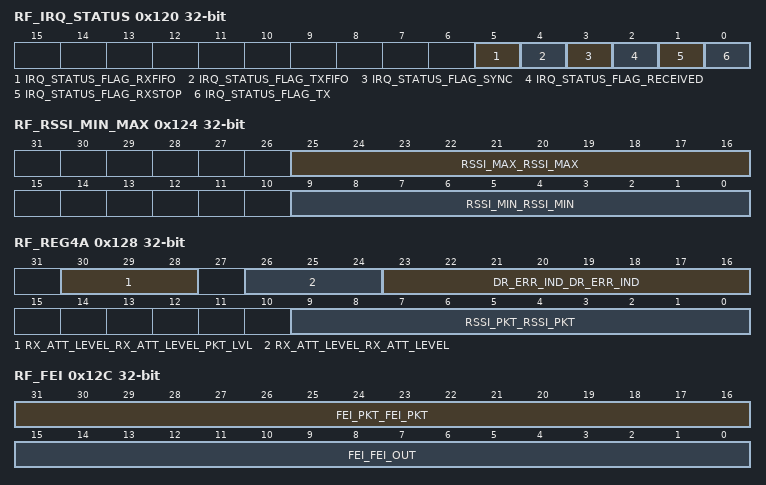
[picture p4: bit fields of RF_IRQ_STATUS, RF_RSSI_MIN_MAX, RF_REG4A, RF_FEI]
0x120 RF_IRQ_STATUS ro — IRQ_STATUS
  [5] IRQ_STATUS_FLAG_RXFIFO — IRQ RXFIFO status
    0=IRQ_STATUS_FLAG_RXFIFO_IDLE (IRQ RXFIFO is not active); 1=IRQ_STATUS_FLAG_RXFIFO_ACTIVE (IRQ RXFIFO is active)
  [4] IRQ_STATUS_FLAG_TXFIFO — IRQ TXFIFO status
    0=IRQ_STATUS_FLAG_TXFIFO_IDLE (IRQ TXFIFO is not active); 1=IRQ_STATUS_FLAG_TXFIFO_ACTIVE (IRQ TXFIFO is active)
  [3] IRQ_STATUS_FLAG_SYNC — IRQ SYNC status
    0=IRQ_STATUS_FLAG_SYNC_IDLE (IRQ SYNC is not active); 1=IRQ_STATUS_FLAG_SYNC_ACTIVE (IRQ SYNC is active)
  [2] IRQ_STATUS_FLAG_RECEIVED — IRQ RECEIVED status
    0=IRQ_STATUS_FLAG_RECEIVED_IDLE (IRQ RECEIVED is not active); 1=IRQ_STATUS_FLAG_RECEIVED_ACTIVE (IRQ RECEIVED is active)
  [1] IRQ_STATUS_FLAG_RXSTOP — IRQ RXSTOP status
    0=IRQ_STATUS_FLAG_RXSTOP_IDLE (IRQ RXSTOP is not active); 1=IRQ_STATUS_FLAG_RXSTOP_ACTIVE (IRQ RXSTOP is active)
  [0] IRQ_STATUS_FLAG_TX — IRQ Tx status
    0=IRQ_STATUS_FLAG_TX_IDLE (IRQ TX is not active); 1=IRQ_STATUS_FLAG_TX_ACTIVE (IRQ TX is active)
0x124 RF_RSSI_MIN_MAX ro — RSSI_MIN_MAX
  [25:16] RSSI_MAX_RSSI_MAX — Maximum RSSI value over a filtering period
    0=RSSI_MAX_RSSI_MAX_DEFAULT
  [9:0] RSSI_MIN_RSSI_MIN — Minimum RSSI value over a filtering period
    0=RSSI_MIN_RSSI_MIN_DEFAULT
0x128 RF_REG4A ro — REG4A
  [30:28] RX_ATT_LEVEL_RX_ATT_LEVEL_PKT_LVL — Rx attenuation level (AGC level) during the packet reception
    0=RX_ATT_LEVEL_RX_ATT_LEVEL_PKT_LVL_DEFAULT
  [26:24] RX_ATT_LEVEL_RX_ATT_LEVEL — Rx attenuation level (AGC level)
    0=RX_ATT_LEVEL_RX_ATT_LEVEL_DEFAULT
  [23:16] DR_ERR_IND_DR_ERR_IND — Data-rate error indicator
    0=DR_ERR_IND_DR_ERR_IND_DEFAULT
  [9:0] RSSI_PKT_RSSI_PKT — Filtered RSSI value sampled during the packet reception
    0=RSSI_PKT_RSSI_PKT_DEFAULT
0x12C RF_FEI ro — FEI
  [31:16] FEI_PKT_FEI_PKT — Frequency error indicator sampled during the packet reception
    0=FEI_PKT_FEI_PKT_DEFAULT
  [15:0] FEI_FEI_OUT — Frequency error indicator
    0=FEI_FEI_OUT_DEFAULT
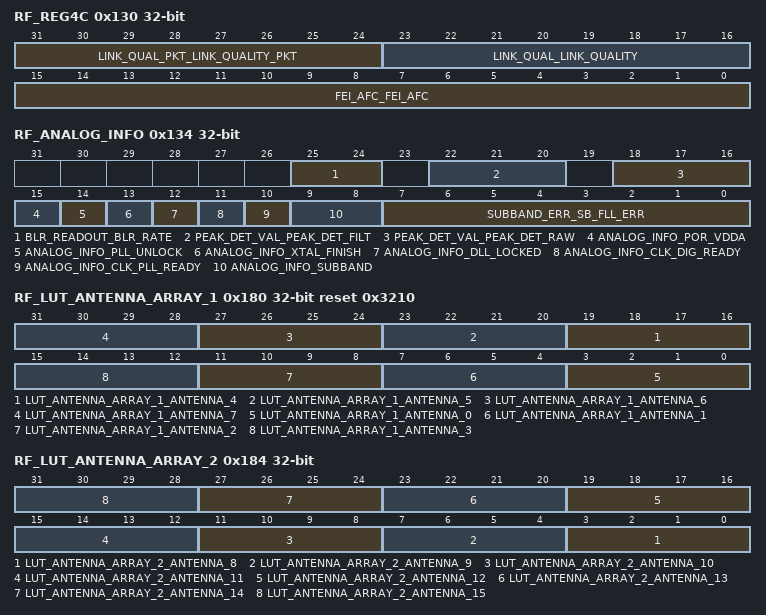
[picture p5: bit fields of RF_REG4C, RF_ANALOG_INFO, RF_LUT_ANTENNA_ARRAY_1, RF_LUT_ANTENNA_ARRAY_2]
0x130 RF_REG4C ro — REG4C
  [31:24] LINK_QUAL_PKT_LINK_QUALITY_PKT — Link quality indicator sampled during the packet reception
    0=LINK_QUAL_PKT_LINK_QUALITY_PKT_DEFAULT
  [23:16] LINK_QUAL_LINK_QUALITY — Instantaneous link quality indicator
    0=LINK_QUAL_LINK_QUALITY_DEFAULT
  [15:0] FEI_AFC_FEI_AFC — Frequency error indicator sampled during the AFC
    0=FEI_AFC_FEI_AFC_DEFAULT
0x134 RF_ANALOG_INFO (reset mask 0x77FFFF) — ANALOG_INFO
  [25:24] BLR_READOUT_BLR_RATE wo — Bluetooth LE long range rate indicator
    0=BLR_READOUT_BLR_RATE_DEFAULT (No action)
  [22:20] PEAK_DET_VAL_PEAK_DET_FILT ro — Distance from the subband center (only available with the FLL method)
    0=PEAK_DET_VAL_PEAK_DET_FILT_DEFAULT
  [18:16] PEAK_DET_VAL_PEAK_DET_RAW ro — Distance from the subband center (only available with the FLL method)
    0=PEAK_DET_VAL_PEAK_DET_RAW_DEFAULT
  [15] ANALOG_INFO_POR_VDDA ro — VDDA LDO disable status
    0=ANALOG_INFO_POR_VDDA_ENABLE (VDDA LDO rnabled); 1=ANALOG_INFO_POR_VDDA_DISABLE (VDDA LDO disabled)
  [14] ANALOG_INFO_PLL_UNLOCK ro — PLL unlock status
    0=ANALOG_INFO_PLL_LOCKED (PLL is locked); 1=ANALOG_INFO_PLL_UNLOCKED (PLL is unlocked)
  [13] ANALOG_INFO_XTAL_FINISH ro — XTAL algorithm status
    0=ANALOG_INFO_XTAL_TRIM_RUNNING (Xtal algorithm has not yet finished); 1=ANALOG_INFO_XTAL_TRIM_FINISHED (Xtal algorithm has finished)
  [12] ANALOG_INFO_DLL_LOCKED ro — DLL lock status
    0=ANALOG_INFO_DLL_UNLOCKED (DLL is unlocked); 1=ANALOG_INFO_DLL_LOCKED (DLL is locked)
  [11] ANALOG_INFO_CLK_DIG_READY ro — Ready signal of the digital clock
    0=ANALOG_INFO_CLK_DIG_NOT_READY (Digital clock not ready); 1=ANALOG_INFO_CLK_DIG_READY (Digital clock ready)
  [10] ANALOG_INFO_CLK_PLL_READY ro — PLL clock status
    0=ANALOG_INFO_CLK_PLL_NOT_READY (PLL clock not ready); 1=ANALOG_INFO_CLK_PLL_READY (PLL clock ready)
  [9:8] ANALOG_INFO_SUBBAND ro — Status of the subband comparator Hi
    0=ANALOG_INFO_SUBBAND_DEFAULT
  [7:0] SUBBAND_ERR_SB_FLL_ERR ro — Distance from the subband center (only available with the FLL method)
    0=SUBBAND_ERR_SB_FLL_ERR_DEFAULT
0x138 RF_SAMPLE_RSSI reset not defined — SAMPLE_RSSI
  [0] SAMPLE_RSSI wo — Sample the thermometric RSSI
    1=SAMPLE_RSSI_SAMPLE_RSSI (Sample the thermometric RSSI)
0x13C RF_RSSI_THERM ro — RSSI_THERM
  [29:0] RSSI_THERM — Thermometric value of the RSSI
    0=RSSI_THERM_DEFAULT
0x180 RF_LUT_ANTENNA_ARRAY_1 reset 0x3210 — LUT_ANTENNA_ARRAY_1
  [4n+3:4n] LUT_ANTENNA_ARRAY_1_ANTENNA_{n} (n=4..7) — Antenna {n} specification
    0=LUT_ANTENNA_ARRAY_1_ANTENNA_{n}_DEFAULT
  [4n+3:4n] LUT_ANTENNA_ARRAY_1_ANTENNA_{n} (n=0..3) — Antenna {n} specification
    {n}=LUT_ANTENNA_ARRAY_1_ANTENNA_{n}_DEFAULT
0x184 RF_LUT_ANTENNA_ARRAY_2 — LUT_ANTENNA_ARRAY_2
  [4n-29:4n-32] LUT_ANTENNA_ARRAY_2_ANTENNA_{n} (n=8..15) — Antenna {n} specification
    0=LUT_ANTENNA_ARRAY_2_ANTENNA_{n}_DEFAULT
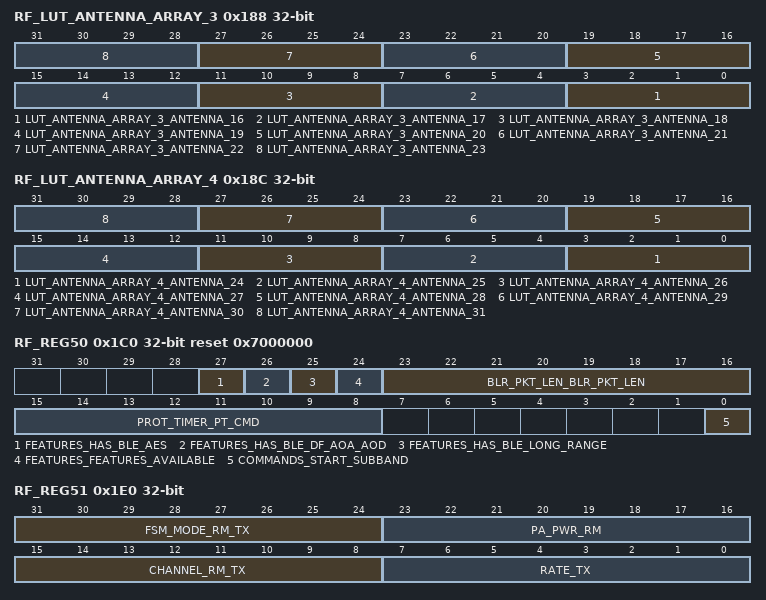
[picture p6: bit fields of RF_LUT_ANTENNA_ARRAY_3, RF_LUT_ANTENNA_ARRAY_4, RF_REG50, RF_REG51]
0x188 RF_LUT_ANTENNA_ARRAY_3 — LUT_ANTENNA_ARRAY_3
  [4n-61:4n-64] LUT_ANTENNA_ARRAY_3_ANTENNA_{n} (n=16..23) — Antenna {n} specification
    0=LUT_ANTENNA_ARRAY_3_ANTENNA_{n}_DEFAULT
0x18C RF_LUT_ANTENNA_ARRAY_4 — LUT_ANTENNA_ARRAY_4
  [4n-93:4n-96] LUT_ANTENNA_ARRAY_4_ANTENNA_{n} (n=24..31) — Antenna {n} specification
    0=LUT_ANTENNA_ARRAY_4_ANTENNA_{n}_DEFAULT
0x1C0 RF_REG50 reset 0x7000000 (reset mask 0xF000000) — REG50
  [27] FEATURES_HAS_BLE_AES ro — Bluetooth AES block availability
    0=FEATURES_HAS_NOT_BLE_AES (AES block is not available); 1=FEATURES_HAS_BLE_AES (AES block is available)
  [26] FEATURES_HAS_BLE_DF_AOA_AOD ro — Bluetooth Direction Finding AoA/AoD feature availability
    0=FEATURES_HAS_NOT_BLE_DF_AOA_AOD (AoA/AoD is not available); 1=FEATURES_HAS_BLE_DF_AOA_AOD (AoA/AoD is available)
  [25] FEATURES_HAS_BLE_LONG_RANGE ro — Bluetooth long range feature availability
    0=FEATURES_HAS_NOT_BLE_LONG_RANGE (Long range is not available); 1=FEATURES_HAS_BLE_LONG_RANGE (Long range is available)
  [24] FEATURES_FEATURES_AVAILABLE ro — Features availability
    0=FEATURES_FEATURES_NOT_AVAILABLE (Features are not available); 1=FEATURES_FEATURES_AVAILABLE (Features are available)
  [23:16] BLR_PKT_LEN_BLR_PKT_LEN wo — Packet length of the BLR packet
    0=BLR_PKT_LEN_BLR_PKT_LEN_DEFAULT
  [15:8] PROT_TIMER_PT_CMD wo — Protocol timer command
    0=PROT_TIMER_PT_CMD_DEFAULT
  [0] COMMANDS_START_SUBBAND wo — Subband selection algorithm
    0=COMMANDS_START_SUBBAND_IDLE (No action); 1=COMMANDS_START_SUBBAND_START (Start the subband selection algorithm)
0x1E0 RF_REG51 — REG51
  [31:24] FSM_MODE_RM_TX — Remapped register of FSM_MODE
    0=FSM_MODE_RM_TX_DEFAULT (The remapped registers are accessible over SPI only)
  [23:16] PA_PWR_RM — Remapped register of PA_PWR
    0=PA_PWR_RM_DEFAULT (The remapped registers are accessible over SPI only)
  [15:8] CHANNEL_RM_TX — Remapped register of CHANNEL
    0=CHANNEL_RM_TX_DEFAULT (The remapped registers are accessible over SPI only)
  [7:0] RATE_TX — Remapped register of BANK
    0=RATE_TX_DEFAULT (The remapped registers are accessible over SPI only)
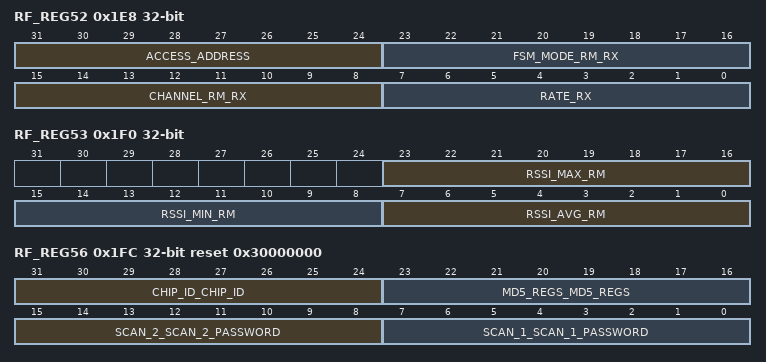
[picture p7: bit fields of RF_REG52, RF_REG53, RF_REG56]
0x1E8 RF_REG52 — REG52
  [31:24] ACCESS_ADDRESS — Remapped register of PATTERN
    0=ACCESS_ADDRESS_DEFAULT (The remapped registers are accessible over SPI only)
  [23:16] FSM_MODE_RM_RX — Remapped register of FSM_MODE
    0=FSM_MODE_RM_RX_DEFAULT (The remapped registers are accessible over SPI only)
  [15:8] CHANNEL_RM_RX — Remapped register of CHANNEL
    0=CHANNEL_RM_RX_DEFAULT (The remapped registers are accessible over SPI only)
  [7:0] RATE_RX — Remapped register of BANK
    0=RATE_RX_DEFAULT (The remapped registers are accessible over SPI only)
0x1F0 RF_REG53 ro — REG53
  [23:16] RSSI_MAX_RM — Remapped register of RSSI_MAX
    0=RSSI_MAX_RM_DEFAULT (The remapped registers are accessible over SPI only)
  [15:8] RSSI_MIN_RM — Remapped register of RSSI_MIN
    0=RSSI_MIN_RM_DEFAULT (The remapped registers are accessible over SPI only)
  [7:0] RSSI_AVG_RM — Remapped register of RSSI_AVG
    0=RSSI_AVG_RM_DEFAULT (The remapped registers are accessible over SPI only)
0x1F4 RF_REG54 reset not defined — REG54
  [7:0] BLR_PACKET_LEN wo — Remapped register of BLR_PACKET_LEN
    0=BLR_PACKET_LEN_DEFAULT (The remapped registers are accessible over SPI only)
0x1F8 RF_REG55 ro — REG55
  [7:0] ITRX_FEATURES — Remapped register of ITRX_FEATURES
    0=ITRX_FEATURES_DEFAULT (The remapped registers are accessible over SPI only)
0x1FC RF_REG56 reset 0x30000000 (reset mask 0xFFFF0000) — REG56
  [31:24] CHIP_ID_CHIP_ID ro — Version of the chip
    48=CHIP_ID_CHIP_ID_DEFAULT
  [23:16] MD5_REGS_MD5_REGS ro — MD5 calculated on the register map file
    0=MD5_REGS_MD5_REGS_DEFAULT
  [15:8] SCAN_2_SCAN_2_PASSWORD wo — SCAN 2 key
    0=SCAN_2_SCAN_2_PASSWORD_DEFAULT
  [7:0] SCAN_1_SCAN_1_PASSWORD wo — SCAN 1 key
    0=SCAN_1_SCAN_1_PASSWORD_DEFAULT
